# ATtiny26 device description
Architecture: AVR8; Family: tinyAVR
Registers are 8-bit, access not given, no defined reset value unless marked. A register's access mark holds for its fields unless they carry their own. Offsets are from the block's base; [hi:lo] are bit positions.

## FUSE — Fuses
Instances: FUSE 0 in fuses
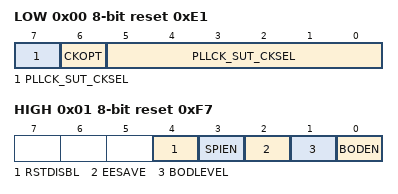
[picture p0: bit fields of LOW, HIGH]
0x00 LOW reset 0xE1
  [6] CKOPT — CKOPT fuse (operation dependent of CKSEL fuses)
  [7,5:0] PLLCK_SUT_CKSEL — Select Clock Source
    1=PLLCLK_1KCK_0MS (PLL Clock; Start-up time: 1K CK + 0 ms); 17=PLLCLK_1KCK_4MS (PLL Clock; Start-up time: 1K CK + 4 ms); 33=PLLCLK_1KCK_64MS (PLL Clock; Start-up time: 1K CK + 64 ms); 49=PLLCLK_16KCK_64MS (PLL Clock; Start-up time: 16K CK + 64 ms); 128=EXTCLK_6CK_0MS (Ext. Clock; Start-up time: 6 CK + 0 ms); 144=EXTCLK_6CK_4MS (Ext. Clock; Start-up time: 6 CK + 4 ms); 160=EXTCLK_6CK_64MS (Ext. Clock; Start-up time: 6 CK + 64 ms); 129=INTRCOSC_1MHZ_6CK_0MS (Int. RC Osc. 1 MHz; Start-up time: 6 CK + 0 ms); 145=INTRCOSC_1MHZ_6CK_4MS (Int. RC Osc. 1 MHz; Start-up time: 6 CK + 4 ms); 161=INTRCOSC_1MHZ_6CK_64MS (Int. RC Osc. 1 MHz; Start-up time: 6 CK + 64 ms); 130=INTRCOSC_2MHZ_6CK_0MS (Int. RC Osc. 2 MHz; Start-up time: 6 CK + 0 ms); 146=INTRCOSC_2MHZ_6CK_4MS (Int. RC Osc. 2 MHz; Start-up time: 6 CK + 4 ms); 162=INTRCOSC_2MHZ_6CK_64MS (Int. RC Osc. 2 MHz; Start-up time: 6 CK + 64 ms); 131=INTRCOSC_4MHZ_6CK_0MS (Int. RC Osc. 4 MHz; Start-up time: 6 CK + 0 ms); 147=INTRCOSC_4MHZ_6CK_4MS (Int. RC Osc. 4 MHz; Start-up time: 6 CK + 4 ms); 163=INTRCOSC_4MHZ_6CK_64MS (Int. RC Osc. 4 MHz; Start-up time: 6 CK + 64 ms); 132=INTRCOSC_8MHZ_6CK_0MS (Int. RC Osc. 8 MHz; Start-up time: 6 CK + 0 ms); 148=INTRCOSC_8MHZ_6CK_4MS (Int. RC Osc. 8 MHz; Start-up time: 6 CK + 4 ms); 164=INTRCOSC_8MHZ_6CK_64MS (Int. RC Osc. 8 MHz; Start-up time: 6 CK + 64 ms); 133=EXTRCOSC_XX_0MHZ9_18CK_0MS (Ext. RC Osc. - 0.9 MHz; Start-up time: 18 CK + 0 ms); 149=EXTRCOSC_XX_0MHZ9_18CK_4MS (Ext. RC Osc. - 0.9 MHz; Start-up time: 18 CK + 4 ms); 165=EXTRCOSC_XX_0MHZ9_18CK_64MS (Ext. RC Osc. - 0.9 MHz; Start-up time: 18 CK + 64 ms); 181=EXTRCOSC_XX_0MHZ9_6CK_4MS (Ext. RC Osc. - 0.9 MHz; Start-up time: 6 CK + 4 ms); 134=EXTRCOSC_0MHZ9_3MHZ_18CK_0MS (Ext. RC Osc. 0.9 MHz - 3.0 MHz; Start-up time: 18 CK + 0 ms); 150=EXTRCOSC_0MHZ9_3MHZ_18CK_4MS (Ext. RC Osc. 0.9 MHz - 3.0 MHz; Start-up time: 18 CK + 4 ms); 166=EXTRCOSC_0MHZ9_3MHZ_18CK_64MS (Ext. RC Osc. 0.9 MHz - 3.0 MHz; Start-up time: 18 CK + 64 ms); 182=EXTRCOSC_0MHZ9_3MHZ_6CK_4MS (Ext. RC Osc. 0.9 MHz - 3.0 MHz; Start-up time: 6 CK + 4 ms); 135=EXTRCOSC_3MHZ_8MHZ_18CK_0MS (Ext. RC Osc. 3.0 MHz - 8.0 MHz; Start-up time: 18 CK + 0 ms); 151=EXTRCOSC_3MHZ_8MHZ_18CK_4MS (Ext. RC Osc. 3.0 MHz - 8.0 MHz; Start-up time: 18 CK + 4 ms); 167=EXTRCOSC_3MHZ_8MHZ_18CK_64MS (Ext. RC Osc. 3.0 MHz - 8.0 MHz; Start-up time: 18 CK + 64 ms); 183=EXTRCOSC_3MHZ_8MHZ_6CK_4MS (Ext. RC Osc. 3.0 MHz - 8.0 MHz; Start-up time: 6 CK + 4 ms); 136=EXTRCOSC_8MHZ_12MHZ_18CK_0MS (Ext. RC Osc. 8.0 MHz - 12.0 MHz; Start-up time: 18 CK + 0 ms); 152=EXTRCOSC_8MHZ_12MHZ_18CK_4MS (Ext. RC Osc. 8.0 MHz - 12.0 MHz; Start-up time: 18 CK + 4 ms); 168=EXTRCOSC_8MHZ_12MHZ_18CK_64MS (Ext. RC Osc. 8.0 MHz - 12.0 MHz; Start-up time: 18 CK + 64 ms); 184=EXTRCOSC_8MHZ_12MHZ_6CK_4MS (Ext. RC Osc. 8.0 MHz - 12.0 MHz; Start-up time: 6 CK + 4 ms); 137=EXTLOFXTAL_1KCK_4MS (Ext. Low-Freq. Crystal; Start-up time: 1K CK + 4 ms); 153=EXTLOFXTAL_1KCK_64MS (Ext. Low-Freq. Crystal; Start-up time: 1K CK + 64 ms); 169=EXTLOFXTAL_32KCK_64MS (Ext. Low-Freq. Crystal; Start-up time: 32K CK + 64 ms); 138=EXTLOFXTALRES_258CK_4MS (Ext. Crystal/Resonator Low Freq.; Start-up time: 258 CK + 4 ms); 154=EXTLOFXTALRES_258CK_64MS (Ext. Crystal/Resonator Low Freq.; Start-up time: 258 CK + 64 ms); 170=EXTLOFXTALRES_1KCK_0MS (Ext. Crystal/Resonator Low Freq.; Start-up time: 1K CK + 0 ms); 186=EXTLOFXTALRES_1KCK_4MS (Ext. Crystal/Resonator Low Freq.; Start-up time: 1K CK + 4 ms); 139=EXTLOFXTALRES_1KCK_64MS (Ext. Crystal/Resonator Low Freq.; Start-up time: 1K CK + 64 ms); 155=EXTLOFXTALRES_16KCK_0MS (Ext. Crystal/Resonator Low Freq.; Start-up time: 16K CK + 0 ms); 171=EXTLOFXTALRES_16KCK_4MS (Ext. Crystal/Resonator Low Freq.; Start-up time: 16K CK + 4 ms); 187=EXTLOFXTALRES_16KCK_64MS (Ext. Crystal/Resonator Low Freq.; Start-up time: 16K CK + 64 ms); 140=EXTMEDFXTALRES_258CK_4MS (Ext. Crystal/Resonator Medium Freq.; Start-up time: 258 CK + 4 ms); 156=EXTMEDFXTALRES_258CK_64MS (Ext. Crystal/Resonator Medium Freq.; Start-up time: 258 CK + 64 ms); 172=EXTMEDFXTALRES_1KCK_0MS (Ext. Crystal/Resonator Medium Freq.; Start-up time: 1K CK + 0 ms); 188=EXTMEDFXTALRES_1KCK_4MS (Ext. Crystal/Resonator Medium Freq.; Start-up time: 1K CK + 4 ms); 141=EXTMEDFXTALRES_1KCK_64MS (Ext. Crystal/Resonator Medium Freq.; Start-up time: 1K CK + 64 ms); 157=EXTMEDFXTALRES_16KCK_0MS (Ext. Crystal/Resonator Medium Freq.; Start-up time: 16K CK + 0 ms); 173=EXTMEDFXTALRES_16KCK_4MS (Ext. Crystal/Resonator Medium Freq.; Start-up time: 16K CK + 4 ms); 189=EXTMEDFXTALRES_16KCK_64MS (Ext. Crystal/Resonator Medium Freq.; Start-up time: 16K CK + 64 ms); 142=EXTHIFXTALRES_258CK_4MS (Ext. Crystal/Resonator High Freq.; Start-up time: 258 CK + 4 ms); 158=EXTHIFXTALRES_258CK_64MS (Ext. Crystal/Resonator High Freq.; Start-up time: 258 CK + 64 ms); 174=EXTHIFXTALRES_1KCK_0MS (Ext. Crystal/Resonator High Freq.; Start-up time: 1K CK + 0 ms); 190=EXTHIFXTALRES_1KCK_4MS (Ext. Crystal/Resonator High Freq.; Start-up time: 1K CK + 4 ms); 143=EXTHIFXTALRES_1KCK_64MS (Ext. Crystal/Resonator High Freq.; Start-up time: 1K CK + 64 ms); 159=EXTHIFXTALRES_16KCK_0MS (Ext. Crystal/Resonator High Freq.; Start-up time: 16K CK + 0 ms); 175=EXTHIFXTALRES_16KCK_4MS (Ext. Crystal/Resonator High Freq.; Start-up time: 16K CK + 4 ms); 191=EXTHIFXTALRES_16KCK_64MS (Ext. Crystal/Resonator High Freq.; Start-up time: 16K CK + 64 ms)
0x01 HIGH reset 0xF7
  [4] RSTDISBL — Reset Disabled (Enable PB7 as i/o pin)
  [3] SPIEN — Serial program downloading (SPI) enabled
  [2] EESAVE — Preserve EEPROM through the Chip Erase cycle
  [1] BODLEVEL — Brownout detector trigger level
    0=4V0 (Brown-out detection at VCC=4.0 V); 1=2V7 (Brown-out detection at VCC=2.7 V)
  [0] BODEN — Brown-out detection enabled
